# PIC32MZ2048EFH064 register map
Vendor: Microchip
Registers are 32-bit, read-write, reset 0x0 unless marked. A register's access mark holds for its fields unless they carry their own. Addresses are absolute, and some are shared; only a register's first bit layout is shown; [hi:lo] are bit positions; {n}, {i} and the like mark numbered series; 'fields as' and 'values as' point back to an identical list.

## clk_cru_upb
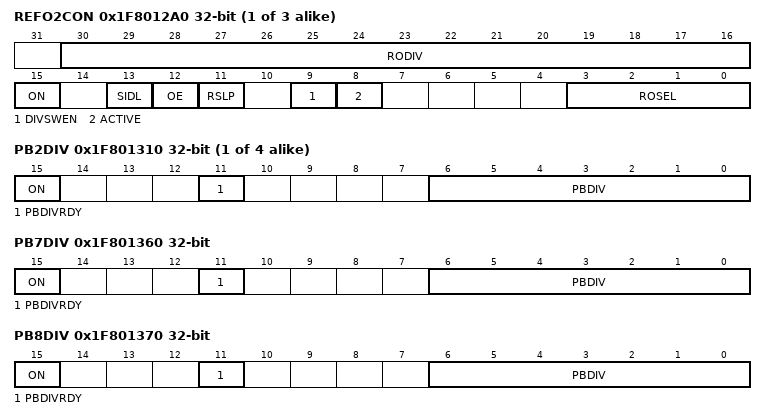
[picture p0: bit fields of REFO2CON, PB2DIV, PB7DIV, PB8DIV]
{0x1F801260+0x20*i} REFO{i}CON (i=2..4)
  [30:16] RODIV, [15] ON, [13] SIDL, [12] OE, [11] RSLP, [9] DIVSWEN, [8] ACTIVE ro, [3:0] ROSEL
{0x1F801270+0x20*i} REFO{i}TRIM (i=2..4)
  [31:23] ROTRIM
{0x1F8012F0+0x10*i} PB{i}DIV reset not defined (i=2..5) — (power-on value ----------------1---1----xxxxxxx)
  [15] ON, [11] PBDIVRDY ro, [6:0] PBDIV
0x1F801360 PB7DIV reset not defined — (power-on value ----------------1---1----xxxxxxx)
  [15] ON, [11] PBDIVRDY ro, [6:0] PBDIV
0x1F801370 PB8DIV reset not defined — (power-on value ----------------1---1----xxxxxxx)
  [15] ON, [11] PBDIVRDY ro, [6:0] PBDIV

## RPINRx
{0x1F801400+4i} INT{i}R (i=1..4)
  [3:0] INT{i}R
{0x1F801410+4i} T{i}CKR (i=2..9)
  [3:0] T{i}CKR
{0x1F801434+4i} IC{i}R (i=1..9)
  [3:0] IC{i}R
0x1F801460 OCFAR
  [3:0] OCFAR
{0x1F801460+8i} U{i}RXR (i=1..6)
  [3:0] U{i}RXR
{0x1F801464+8i} U{i}CTSR (i=1..6)
  [3:0] U{i}CTSR
{0x1F801490+0xC*i} SDI{i}R (i=1..4)
  [3:0] SDI{i}R
{0x1F801494+0xC*i} SS{i}R (i=1..4)
  [3:0] SS{i}R
0x1F8014E0 C1RXR
  [3:0] C1RXR
0x1F8014E4 C2RXR
  [3:0] C2RXR
0x1F8014E8 REFCLKI1R
  [3:0] REFCLKI1R
0x1F8014F0 REFCLKI3R
  [3:0] REFCLKI3R
0x1F8014F4 REFCLKI4R
  [3:0] REFCLKI4R

## RPORx
{0x1F801540+4i} RPB{i}R (i=0..3)
  [3:0] RPB{i}R
{0x1F801540+4i} RPB{i}R (i=5..10)
  [3:0] RPB{i}R
0x1F801578 RPB14R
  [3:0] RPB14R
0x1F80157C RPB15R
  [3:0] RPB15R
0x1F8015B4 RPC13R
  [3:0] RPC13R
0x1F8015B8 RPC14R
  [3:0] RPC14R
{0x1F8015C0+4i} RPD{i}R (i=0..5)
  [3:0] RPD{i}R
{0x1F8015C0+4i} RPD{i}R (i=9..11)
  [3:0] RPD{i}R
0x1F80160C RPE3R
  [3:0] RPE3R
0x1F801614 RPE5R
  [3:0] RPE5R
0x1F801640 RPF0R
  [3:0] RPF0R
0x1F801644 RPF1R
  [3:0] RPF1R
{0x1F801640+4i} RPF{i}R (i=3..5)
  [3:0] RPF{i}R
{0x1F801680+4i} RPG{i}R (i=6..9)
  [3:0] RPG{i}R

## dma_bvci
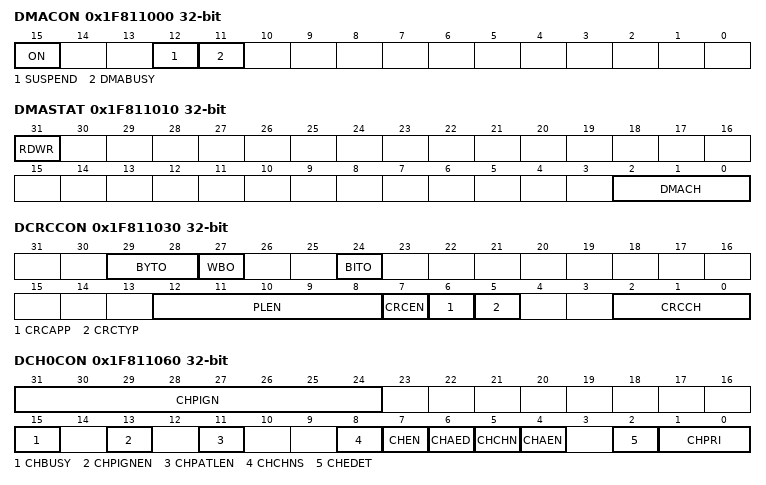
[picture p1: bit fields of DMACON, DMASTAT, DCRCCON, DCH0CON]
0x1F811000 DMACON
  [15] ON, [12] SUSPEND, [11] DMABUSY
0x1F811010 DMASTAT ro
  [31] RDWR, [2:0] DMACH
0x1F811020 DMAADDR ro
0x1F811030 DCRCCON
  [29:28] BYTO, [27] WBO, [24] BITO, [12:8] PLEN, [7] CRCEN, [6] CRCAPP, [5] CRCTYP, [2:0] CRCCH
0x1F811040 DCRCDATA
0x1F811050 DCRCXOR
0x1F811060 DCH0CON reset not defined — (power-on value xxxxxxxx--------0-0-0--00000-000)
  [31:24] CHPIGN, [15] CHBUSY, [13] CHPIGNEN, [11] CHPATLEN, [8] CHCHNS, [7] CHEN, [6] CHAED, [5] CHCHN, [4] CHAEN, [2] CHEDET ro, [1:0] CHPRI
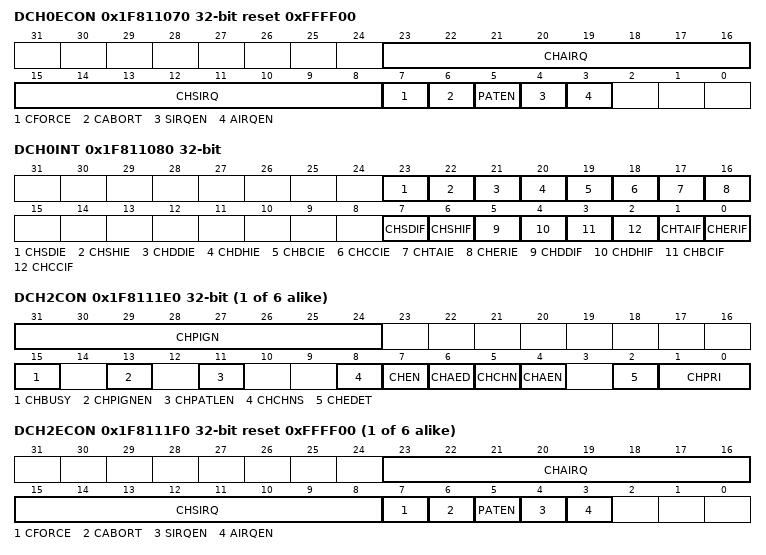
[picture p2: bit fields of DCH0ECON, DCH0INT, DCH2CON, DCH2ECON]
0x1F811070 DCH0ECON reset 0xFFFF00
  [23:16] CHAIRQ, [15:8] CHSIRQ, [7] CFORCE, [6] CABORT, [5] PATEN, [4] SIRQEN, [3] AIRQEN
0x1F811080 DCH0INT
  [23] CHSDIE, [22] CHSHIE, [21] CHDDIE, [20] CHDHIE, [19] CHBCIE, [18] CHCCIE, [17] CHTAIE, [16] CHERIE, [7] CHSDIF, [6] CHSHIF, [5] CHDDIF, [4] CHDHIF, [3] CHBCIF, [2] CHCCIF, [1] CHTAIF, [0] CHERIF
0x1F811090 DCH0SSA reset not defined — (power-on value xxxxxxxxxxxxxxxxxxxxxxxxxxxxxxxx)
  [31:0] CHSSA
0x1F8110A0 DCH0DSA reset not defined — (power-on value xxxxxxxxxxxxxxxxxxxxxxxxxxxxxxxx)
  [31:0] CHDSA
0x1F8110B0 DCH0SSIZ reset not defined — (power-on value ----------------xxxxxxxxxxxxxxxx)
  [15:0] CHSSIZ
0x1F8110C0 DCH0DSIZ reset not defined — (power-on value ----------------xxxxxxxxxxxxxxxx)
  [15:0] CHDSIZ
0x1F8110D0 DCH0SPTR
  [15:0] CHSPTR
0x1F8110E0 DCH0DPTR
  [15:0] CHDPTR
0x1F8110F0 DCH0CSIZ reset not defined — (power-on value ----------------xxxxxxxxxxxxxxxx)
  [15:0] CHCSIZ
0x1F811100 DCH0CPTR
  [15:0] CHCPTR
0x1F811110 DCH0DAT reset not defined — (power-on value ----------------xxxxxxxxxxxxxxxx)
  [15:0] CHPDAT
{0x1F811060+0xC0*i} DCH{i}CON reset not defined (i=2..7) — (power-on value xxxxxxxx--------0-0-0--00000-000)
  fields as DCH0CON
{0x1F811070+0xC0*i} DCH{i}ECON reset 0xFFFF00 (i=2..7)
  fields as DCH0ECON
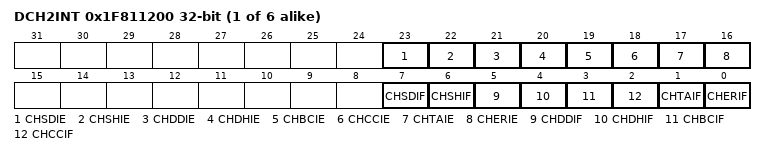
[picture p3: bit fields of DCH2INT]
{0x1F811080+0xC0*i} DCH{i}INT (i=2..7)
  fields as DCH0INT
{0x1F811090+0xC0*i} DCH{i}SSA reset not defined (i=2..7) — (power-on value xxxxxxxxxxxxxxxxxxxxxxxxxxxxxxxx)
  [31:0] CHSSA
{0x1F8110A0+0xC0*i} DCH{i}DSA reset not defined (i=2..7) — (power-on value xxxxxxxxxxxxxxxxxxxxxxxxxxxxxxxx)
  [31:0] CHDSA
{0x1F8110B0+0xC0*i} DCH{i}SSIZ reset not defined (i=2..7) — (power-on value ----------------xxxxxxxxxxxxxxxx)
  [15:0] CHSSIZ
{0x1F8110C0+0xC0*i} DCH{i}DSIZ reset not defined (i=2..7) — (power-on value ----------------xxxxxxxxxxxxxxxx)
  [15:0] CHDSIZ
{0x1F8110D0+0xC0*i} DCH{i}SPTR (i=2..7)
  [15:0] CHSPTR
{0x1F8110E0+0xC0*i} DCH{i}DPTR (i=2..7)
  [15:0] CHDPTR
{0x1F8110F0+0xC0*i} DCH{i}CSIZ reset not defined (i=2..7) — (power-on value ----------------xxxxxxxxxxxxxxxx)
  [15:0] CHCSIZ
{0x1F811100+0xC0*i} DCH{i}CPTR (i=2..7)
  [15:0] CHCPTR
{0x1F811110+0xC0*i} DCH{i}DAT reset not defined (i=2..7) — (power-on value ----------------xxxxxxxxxxxxxxxx)
  [15:0] CHPDAT
